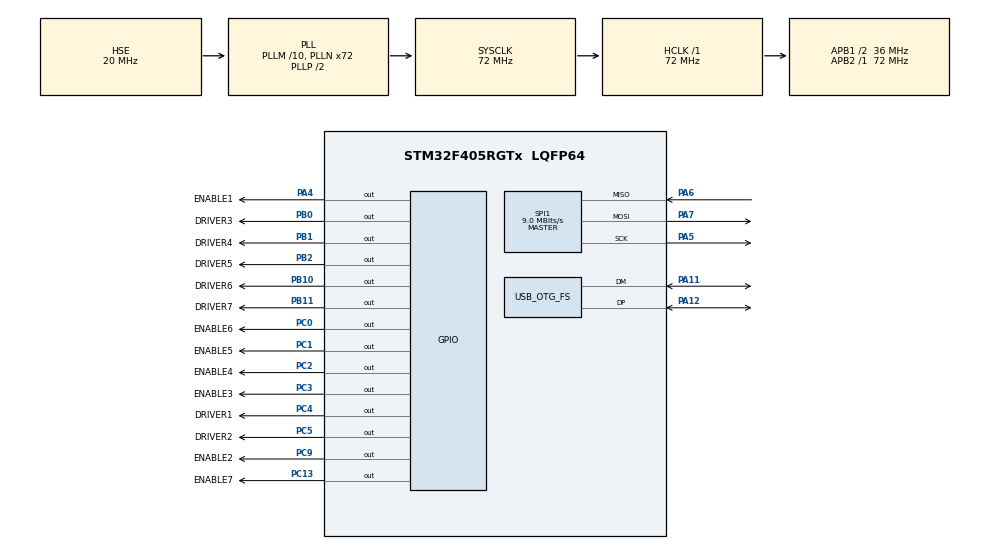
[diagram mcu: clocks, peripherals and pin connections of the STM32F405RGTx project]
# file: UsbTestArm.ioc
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Mcu.Family=STM32F4
Mcu.Name=STM32F405RGTx
Mcu.Package=LQFP64
NVIC.OTG_FS_IRQn=true\:0\:0\:false\:false\:true\:false\:true\:true
NVIC.PriorityGroup=NVIC_PRIORITYGROUP_4
PA11.Mode=Device_Only
PA11.Signal=USB_OTG_FS_DM
PA12.Mode=Device_Only
PA12.Signal=USB_OTG_FS_DP
PA4.GPIO_Label=ENABLE1
PA4.Signal=GPIO_Output
PA5.Mode=Full_Duplex_Master
PA5.Signal=SPI1_SCK
PA6.Mode=Full_Duplex_Master
PA6.Signal=SPI1_MISO
PA7.Mode=Full_Duplex_Master
PA7.Signal=SPI1_MOSI
PB0.GPIO_Label=DRIVER3
PB0.PinState=GPIO_PIN_SET
PB0.Signal=GPIO_Output
PB1.GPIO_Label=DRIVER4
PB1.PinState=GPIO_PIN_SET
PB1.Signal=GPIO_Output
PB10.GPIO_Label=DRIVER6
PB10.PinState=GPIO_PIN_SET
PB10.Signal=GPIO_Output
PB11.GPIO_Label=DRIVER7
PB11.PinState=GPIO_PIN_SET
PB11.Signal=GPIO_Output
PB2.GPIO_Label=DRIVER5
PB2.PinState=GPIO_PIN_SET
PB2.Signal=GPIO_Output
PC0.GPIO_Label=ENABLE6
PC0.Signal=GPIO_Output
PC1.GPIO_Label=ENABLE5
PC1.Signal=GPIO_Output
PC13-ANTI_TAMP.GPIO_Label=ENABLE7
PC13-ANTI_TAMP.Signal=GPIO_Output
PC2.GPIO_Label=ENABLE4
PC2.Signal=GPIO_Output
PC3.GPIO_Label=ENABLE3
PC3.Signal=GPIO_Output
PC4.GPIO_Label=DRIVER1
PC4.PinState=GPIO_PIN_SET
PC4.Signal=GPIO_Output
PC5.GPIO_Label=DRIVER2
PC5.PinState=GPIO_PIN_SET
PC5.Signal=GPIO_Output
PC9.GPIO_Label=ENABLE2
PC9.Signal=GPIO_Output
PH0-OSC_IN.Mode=HSE-External-Oscillator
PH0-OSC_IN.Signal=RCC_OSC_IN
PH1-OSC_OUT.Mode=HSE-External-Oscillator
PH1-OSC_OUT.Signal=RCC_OSC_OUT
ProjectManager.HeapSize=0x200
ProjectManager.StackSize=0x400
ProjectManager.TargetToolchain=STM32CubeIDE
RCC.48MHZClocksFreq_Value=48000000
RCC.AHBFreq_Value=72000000
RCC.APB1CLKDivider=RCC_HCLK_DIV2
RCC.APB1Freq_Value=36000000
RCC.APB1TimFreq_Value=72000000
RCC.APB2Freq_Value=72000000
RCC.APB2TimFreq_Value=72000000
RCC.CortexFreq_Value=72000000
RCC.HCLKFreq_Value=72000000
RCC.HSE_VALUE=20000000
RCC.HSI_VALUE=16000000
RCC.LSE_VALUE=32768
RCC.PLLM=10
RCC.PLLN=72
RCC.PLLQ=3
RCC.SYSCLKFreq_VALUE=72000000
RCC.SYSCLKSource=RCC_SYSCLKSOURCE_PLLCLK
RCC.VCOOutputFreq_Value=144000000
SPI1.BaudRatePrescaler=SPI_BAUDRATEPRESCALER_8
SPI1.CLKPhase=SPI_PHASE_2EDGE
SPI1.CLKPolarity=SPI_POLARITY_HIGH
SPI1.CalculateBaudRate=9.0 MBits/s
SPI1.DataSize=SPI_DATASIZE_8BIT
SPI1.Direction=SPI_DIRECTION_2LINES
SPI1.Mode=SPI_MODE_MASTER
SPI1.VirtualType=VM_MASTER
USB_DEVICE.CLASS_NAME_FS=CDC
USB_DEVICE.VirtualMode-CDC_FS=Cdc
USB_DEVICE.VirtualModeFS=Cdc_FS
USB_OTG_FS.VirtualMode=Device_Only
VP_USB_DEVICE_VS_USB_DEVICE_CDC_FS.Mode=CDC_FS
board=custom

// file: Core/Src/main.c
/* USER CODE BEGIN Header */
/**
  ******************************************************************************
  * @file           : main.c
  * @brief          : Main program body
  ******************************************************************************
  * @attention
  *
  * Copyright (c) 2025 STMicroelectronics.
  * All rights reserved.
  *
  * This software is licensed under terms that can be found in the LICENSE file
  * in the root directory of this software component.
  * If no LICENSE file comes with this software, it is provided AS-IS.
  *
  ******************************************************************************
  */
/* USER CODE END Header */
#include "main.h"
#include "usb_device.h"

/* USER CODE BEGIN Includes */
#include "TMC2660.h"
#include "USB.h"
/* USER CODE END Includes */

SPI_HandleTypeDef hspi1;

/* USER CODE BEGIN PV */
extern volatile uint8_t data_received;
extern uint8_t rx_buffer[];
extern uint32_t data_size;

/* USER CODE END PV */

void SystemClock_Config(void);
static void MX_GPIO_Init(void);
static void MX_SPI1_Init(void);

int main(void)
{

  /* MCU Configuration--------------------------------------------------------*/

  /* Reset of all peripherals, Initializes the Flash interface and the Systick. */
  HAL_Init();

  /* Configure the system clock */
  SystemClock_Config();

  /* Initialize all configured peripherals */
  MX_GPIO_Init();
  MX_USB_DEVICE_Init();
  MX_SPI1_Init();
  /* USER CODE BEGIN 2 */
  InitTMC2660();
  TMC2660_Config current_config;
      ReadTMC2660Config(0, &current_config);
  /* USER CODE END 2 */

  /* Infinite loop */
  /* USER CODE BEGIN WHILE */
  while (1)
  {
	  if(data_received) {
	      // Add null terminator to received data
	      rx_buffer[data_size] = '\0';
	      // Parse and execute command
	      parse_command((char*)rx_buffer);
	      data_received = 0;
	  }
    /* USER CODE END WHILE */

  }
}

void SystemClock_Config(void)
{
  RCC_OscInitTypeDef RCC_OscInitStruct = {0};
  RCC_ClkInitTypeDef RCC_ClkInitStruct = {0};

  /** Configure the main internal regulator output voltage
  */
  __HAL_RCC_PWR_CLK_ENABLE();
  __HAL_PWR_VOLTAGESCALING_CONFIG(PWR_REGULATOR_VOLTAGE_SCALE1);

  /** Initializes the RCC Oscillators according to the specified parameters
  * in the RCC_OscInitTypeDef structure.
  */
  RCC_OscInitStruct.OscillatorType = RCC_OSCILLATORTYPE_HSE;
  RCC_OscInitStruct.HSEState = RCC_HSE_ON;
  RCC_OscInitStruct.PLL.PLLState = RCC_PLL_ON;
  RCC_OscInitStruct.PLL.PLLSource = RCC_PLLSOURCE_HSE;
  RCC_OscInitStruct.PLL.PLLM = 10;
  RCC_OscInitStruct.PLL.PLLN = 72;
  RCC_OscInitStruct.PLL.PLLP = RCC_PLLP_DIV2;
  RCC_OscInitStruct.PLL.PLLQ = 3;
  if (HAL_RCC_OscConfig(&RCC_OscInitStruct) != HAL_OK)
  {
    Error_Handler();
  }

  /** Initializes the CPU, AHB and APB buses clocks
  */
  RCC_ClkInitStruct.ClockType = RCC_CLOCKTYPE_HCLK|RCC_CLOCKTYPE_SYSCLK
                              |RCC_CLOCKTYPE_PCLK1|RCC_CLOCKTYPE_PCLK2;
  RCC_ClkInitStruct.SYSCLKSource = RCC_SYSCLKSOURCE_PLLCLK;
  RCC_ClkInitStruct.AHBCLKDivider = RCC_SYSCLK_DIV1;
  RCC_ClkInitStruct.APB1CLKDivider = RCC_HCLK_DIV2;
  RCC_ClkInitStruct.APB2CLKDivider = RCC_HCLK_DIV1;

  if (HAL_RCC_ClockConfig(&RCC_ClkInitStruct, FLASH_LATENCY_2) != HAL_OK)
  {
    Error_Handler();
  }
}

static void MX_SPI1_Init(void)
{

  /* SPI1 parameter configuration*/
  hspi1.Instance = SPI1;
  hspi1.Init.Mode = SPI_MODE_MASTER;
  hspi1.Init.Direction = SPI_DIRECTION_2LINES;
  hspi1.Init.DataSize = SPI_DATASIZE_8BIT;
  hspi1.Init.CLKPolarity = SPI_POLARITY_HIGH;
  hspi1.Init.CLKPhase = SPI_PHASE_2EDGE;
  hspi1.Init.NSS = SPI_NSS_SOFT;
  hspi1.Init.BaudRatePrescaler = SPI_BAUDRATEPRESCALER_8;
  hspi1.Init.FirstBit = SPI_FIRSTBIT_MSB;
  hspi1.Init.TIMode = SPI_TIMODE_DISABLE;
  hspi1.Init.CRCCalculation = SPI_CRCCALCULATION_DISABLE;
  hspi1.Init.CRCPolynomial = 10;
  if (HAL_SPI_Init(&hspi1) != HAL_OK)
  {
    Error_Handler();
  }

}

static void MX_GPIO_Init(void)
{
  GPIO_InitTypeDef GPIO_InitStruct = {0};

  /* GPIO Ports Clock Enable */
  __HAL_RCC_GPIOC_CLK_ENABLE();
  __HAL_RCC_GPIOH_CLK_ENABLE();
  __HAL_RCC_GPIOA_CLK_ENABLE();
  __HAL_RCC_GPIOB_CLK_ENABLE();

  /*Configure GPIO pin Output Level */
  HAL_GPIO_WritePin(GPIOC, ENABLE7_Pin|ENABLE6_Pin|ENABLE5_Pin|ENABLE4_Pin
                          |ENABLE3_Pin|ENABLE2_Pin, GPIO_PIN_RESET);

  /*Configure GPIO pin Output Level */
  HAL_GPIO_WritePin(ENABLE1_GPIO_Port, ENABLE1_Pin, GPIO_PIN_RESET);

  /*Configure GPIO pin Output Level */
  HAL_GPIO_WritePin(GPIOC, DRIVER1_Pin|DRIVER2_Pin, GPIO_PIN_SET);

  /*Configure GPIO pin Output Level */
  HAL_GPIO_WritePin(GPIOB, DRIVER3_Pin|DRIVER4_Pin|DRIVER5_Pin|DRIVER6_Pin
                          |DRIVER7_Pin, GPIO_PIN_SET);

  /*Configure GPIO pins : ENABLE7_Pin ENABLE6_Pin ENABLE5_Pin ENABLE4_Pin
                           ENABLE3_Pin DRIVER1_Pin DRIVER2_Pin ENABLE2_Pin */
  GPIO_InitStruct.Pin = ENABLE7_Pin|ENABLE6_Pin|ENABLE5_Pin|ENABLE4_Pin
                          |ENABLE3_Pin|DRIVER1_Pin|DRIVER2_Pin|ENABLE2_Pin;
  GPIO_InitStruct.Mode = GPIO_MODE_OUTPUT_PP;
  GPIO_InitStruct.Pull = GPIO_NOPULL;
  GPIO_InitStruct.Speed = GPIO_SPEED_FREQ_LOW;
  HAL_GPIO_Init(GPIOC, &GPIO_InitStruct);

  /*Configure GPIO pin : ENABLE1_Pin */
  GPIO_InitStruct.Pin = ENABLE1_Pin;
  GPIO_InitStruct.Mode = GPIO_MODE_OUTPUT_PP;
  GPIO_InitStruct.Pull = GPIO_NOPULL;
  GPIO_InitStruct.Speed = GPIO_SPEED_FREQ_LOW;
  HAL_GPIO_Init(ENABLE1_GPIO_Port, &GPIO_InitStruct);

  /*Configure GPIO pins : DRIVER3_Pin DRIVER4_Pin DRIVER5_Pin DRIVER6_Pin
                           DRIVER7_Pin */
  GPIO_InitStruct.Pin = DRIVER3_Pin|DRIVER4_Pin|DRIVER5_Pin|DRIVER6_Pin
                          |DRIVER7_Pin;
  GPIO_InitStruct.Mode = GPIO_MODE_OUTPUT_PP;
  GPIO_InitStruct.Pull = GPIO_NOPULL;
  GPIO_InitStruct.Speed = GPIO_SPEED_FREQ_LOW;
  HAL_GPIO_Init(GPIOB, &GPIO_InitStruct);

}

void Error_Handler(void)
{
  __disable_irq();
  while (1)
  {
  }
}
